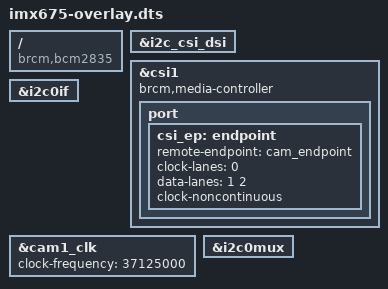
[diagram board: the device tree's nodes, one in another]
// SPDX-License-Identifier: GPL-2.0-only
// Partial definitions for IMX675 camera module on VC I2C bus
/dts-v1/;
/plugin/;

#include <dt-bindings/gpio/gpio.h>

/{
	compatible = "brcm,bcm2835";

	i2c_frag: fragment@0 {
		target = <&i2c_csi_dsi>;
		__overlay__ {
			#address-cells = <1>;
			#size-cells = <0>;
			status = "okay";

			#include "imx675.dtsi"
		};
	};

	csi_frag: fragment@1 {
		target = <&csi1>;
		csi: __overlay__ {
			status = "okay";
			brcm,media-controller;

			port {
				csi_ep: endpoint {
					remote-endpoint = <&cam_endpoint>;
					clock-lanes = <0>;
					data-lanes = <1 2>;
					clock-noncontinuous;
				};
			};
		};
	};

	fragment@2 {
		target = <&i2c0if>;
		__overlay__ {
			status = "okay";
		};
	};

	clk_frag: fragment@3 {
		target = <&cam1_clk>;
		cam_clk: __overlay__ {
			status = "okay";
			clock-frequency = <37125000>;
		};
	};

	fragment@4 {
		target = <&i2c0mux>;
		__overlay__ {
			status = "okay";
		};
	};

	fragment@201 {
		target = <&cam_endpoint>;
		__dormant__ {
			data-lanes = <1 2 3 4>;
		};
	};

	fragment@202 {
		target = <&csi_ep>;
		__dormant__ {
			data-lanes = <1 2 3 4>;
		};
	};

	fragment@203 {
		target = <&cam_endpoint>;
		__dormant__ {
			link-frequencies = /bits/ 64
					<1039500000
					 891000000
					 720000000
					 594000000
					 445500000
					 360000000
					 297000000>;
		};
	};

	__overrides__ {
		4lane = <0>, "+201+202";
		clock-frequency = <&cam_clk>,"clock-frequency:0",
				  <&cam_node>,"clock-frequency:0";
		rotation = <&cam_node>,"rotation:0";
		orientation = <&cam_node>,"orientation:0";
		media-controller = <&csi>,"brcm,media-controller?";
		cam0 = <&i2c_frag>, "target:0=",<&i2c_vc>,
		       <&csi_frag>, "target:0=",<&csi0>,
		       <&clk_frag>, "target:0=",<&cam0_clk>,
		       <&cam_node>, "clocks:0=",<&cam0_clk>,
		       <&cam_node>, "vdda-supply:0=",<&cam0_reg>;
		link-frequency = <&cam_endpoint>,"link-frequencies#0";
		all-link-frequencies = <0>, "+203";
		mono = <0>, "";
	};
};
